AUTOSAR XML (schema 4-0-3)
package /AppBal
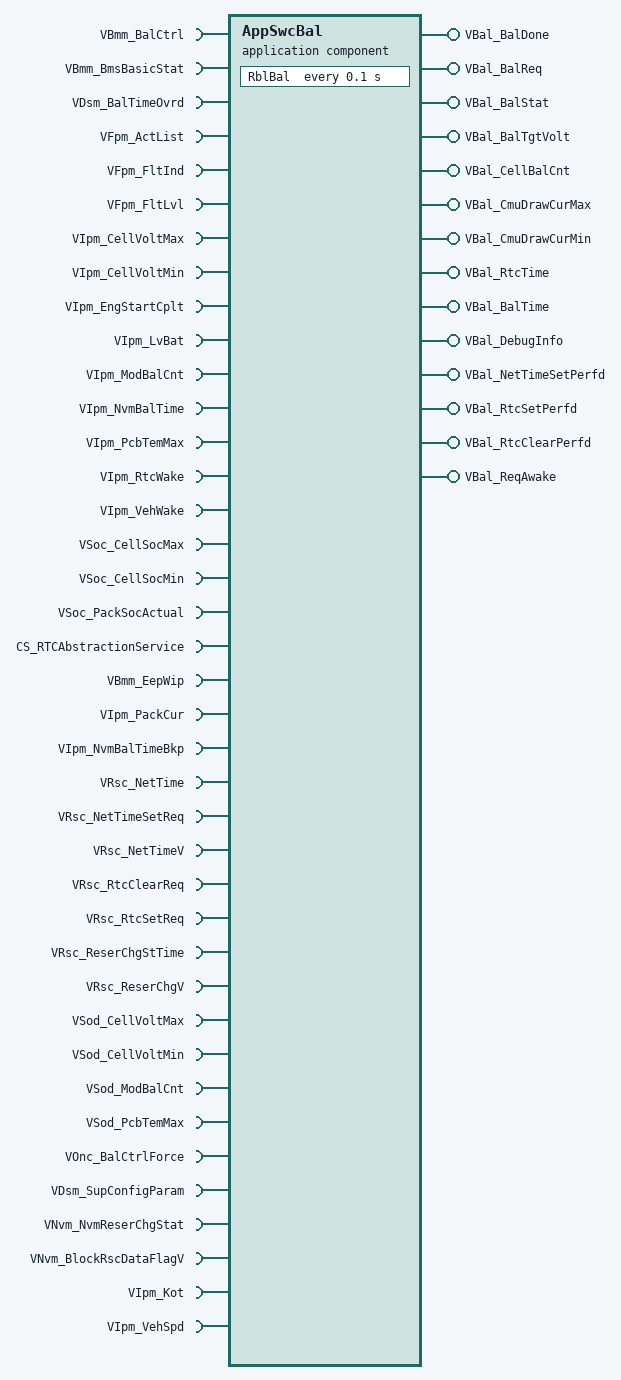
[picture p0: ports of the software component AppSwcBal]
  application sw component type AppSwcBal
    18 x require port:
      VBmm_BalCtrl: nonqueued-receiver-com-spec=Enum, required-interface=VBmm_BalCtrl
      VBmm_BmsBasicStat: nonqueued-receiver-com-spec=Enum, required-interface=VBmm_BmsBasicStat
      VDsm_BalTimeOvrd: nonqueued-receiver-com-spec=Sec, required-interface=VDsm_BalTimeOvrd
      VFpm_ActList: nonqueued-receiver-com-spec=Enum, required-interface=VFpm_ActList
      VFpm_FltInd: nonqueued-receiver-com-spec=Array, required-interface=VFpm_FltInd
      VFpm_FltLvl: nonqueued-receiver-com-spec=Enum, required-interface=VFpm_FltLvl
      VIpm_CellVoltMax: nonqueued-receiver-com-spec=V, required-interface=VIpm_CellVoltMax
      VIpm_CellVoltMin: nonqueued-receiver-com-spec=V, required-interface=VIpm_CellVoltMin
      VIpm_EngStartCplt: nonqueued-receiver-com-spec=Flg, required-interface=VIpm_EngStartCplt
      VIpm_LvBat: nonqueued-receiver-com-spec=V, required-interface=VIpm_LvBat
      VIpm_ModBalCnt: nonqueued-receiver-com-spec=Cnt, required-interface=VIpm_ModBalCnt
      VIpm_NvmBalTime: nonqueued-receiver-com-spec=Sec, required-interface=VIpm_NvmBalTime
      VIpm_PcbTemMax: nonqueued-receiver-com-spec=C, required-interface=VIpm_PcbTemMax
      VIpm_RtcWake: nonqueued-receiver-com-spec=Flg, required-interface=VIpm_RtcWake
      VIpm_VehWake: nonqueued-receiver-com-spec=Flg, required-interface=VIpm_VehWake
      VSoc_CellSocMax: nonqueued-receiver-com-spec=Pct, required-interface=VSoc_CellSocMax
      VSoc_CellSocMin: nonqueued-receiver-com-spec=Pct, required-interface=VSoc_CellSocMin
      VSoc_PackSocActual: nonqueued-receiver-com-spec=Pct, required-interface=VSoc_PackSocActual
    8 x provide port:
      VBal_BalDone: nonqueued-sender-com-spec=Flg, provided-interface=VBal_BalDone
      VBal_BalReq: nonqueued-sender-com-spec=Flg, provided-interface=VBal_BalReq
      VBal_BalStat: nonqueued-sender-com-spec=Enum, provided-interface=VBal_BalStat
      VBal_BalTgtVolt: nonqueued-sender-com-spec{data-element=V, init-value=fields=[5095, 0, 0, 0]}, provided-interface=VBal_BalTgtVolt
      VBal_CellBalCnt: nonqueued-sender-com-spec=Cnt, provided-interface=VBal_CellBalCnt
      VBal_CmuDrawCurMax: nonqueued-sender-com-spec=A, provided-interface=VBal_CmuDrawCurMax
      VBal_CmuDrawCurMin: nonqueued-sender-com-spec=A, provided-interface=VBal_CmuDrawCurMin
      VBal_RtcTime: nonqueued-sender-com-spec=Structure, provided-interface=VBal_RtcTime
    require port CS_RTCAbstractionService: required-interface=CS_RTCAbstractionService
    provide port VBal_BalTime: nonqueued-sender-com-spec=Sec, provided-interface=VBal_BalTime
    require port VBmm_EepWip: nonqueued-receiver-com-spec=Flg, required-interface=VBmm_EepWip
    require port VIpm_PackCur: nonqueued-receiver-com-spec=A, required-interface=VIpm_PackCur
    require port VIpm_NvmBalTimeBkp: nonqueued-receiver-com-spec=Sec, required-interface=VIpm_NvmBalTimeBkp
    provide port VBal_DebugInfo: nonqueued-sender-com-spec=Array, provided-interface=VBal_DebugInfo
    5 x require port:
      VRsc_NetTime: nonqueued-receiver-com-spec=Array, required-interface=VRsc_NetTime
      VRsc_NetTimeSetReq: nonqueued-receiver-com-spec=Flg, required-interface=VRsc_NetTimeSetReq
      VRsc_NetTimeV: nonqueued-receiver-com-spec=Flg, required-interface=VRsc_NetTimeV
      VRsc_RtcClearReq: nonqueued-receiver-com-spec=Flg, required-interface=VRsc_RtcClearReq
      VRsc_RtcSetReq: nonqueued-receiver-com-spec=Flg, required-interface=VRsc_RtcSetReq
    provide port VBal_NetTimeSetPerfd: nonqueued-sender-com-spec=Flg, provided-interface=VBal_NetTimeSetPerfd
    provide port VBal_RtcSetPerfd: nonqueued-sender-com-spec=Flg, provided-interface=VBal_RtcSetPerfd
    provide port VBal_RtcClearPerfd: nonqueued-sender-com-spec=Flg, provided-interface=VBal_RtcClearPerfd
    7 x require port:
      VRsc_ReserChgStTime: nonqueued-receiver-com-spec=Array, required-interface=VRsc_ReserChgStTime
      VRsc_ReserChgV: nonqueued-receiver-com-spec=Flg, required-interface=VRsc_ReserChgV
      VSod_CellVoltMax: nonqueued-receiver-com-spec=V, required-interface=VSod_CellVoltMax
      VSod_CellVoltMin: nonqueued-receiver-com-spec=V, required-interface=VSod_CellVoltMin
      VSod_ModBalCnt: nonqueued-receiver-com-spec=Cnt, required-interface=VSod_ModBalCnt
      VSod_PcbTemMax: nonqueued-receiver-com-spec=C, required-interface=VSod_PcbTemMax
      VOnc_BalCtrlForce: nonqueued-receiver-com-spec=Enum, required-interface=VOnc_BalCtrlForce
    provide port VBal_ReqAwake: nonqueued-sender-com-spec=Flg, provided-interface=VBal_ReqAwake
    5 x require port:
      VDsm_SupConfigParam: nonqueued-receiver-com-spec=Enum, required-interface=VDsm_SupConfigParam
      VNvm_NvmReserChgStat: nonqueued-receiver-com-spec=Enum, required-interface=VNvm_NvmReserChgStat
      VNvm_BlockRscDataFlagV: nonqueued-receiver-com-spec=Flg, required-interface=VNvm_BlockRscDataFlagV
      VIpm_Kot: nonqueued-receiver-com-spec=Sec, required-interface=VIpm_Kot
      VIpm_VehSpd: nonqueued-receiver-com-spec=Kph, required-interface=VIpm_VehSpd
    behavior IbvBal
      timing event TeBal: start-on-event=RblBal, period=0.1
      runnable RblBal: symbol=sym_RblBal
        data-receive-point-by-arguments:
          38 x access:
            ArgRecPoint_VBmm_BalCtrl_Enum: accessed-variable=VBmm_BalCtrl.Enum
            ArgRecPoint_VBmm_BmsBasicStat_Enum: accessed-variable=VBmm_BmsBasicStat.Enum
            ArgRecPoint_VDsm_BalTimeOvrd_Sec: accessed-variable=VDsm_BalTimeOvrd.Sec
            ArgRecPoint_VFpm_ActList_Enum: accessed-variable=VFpm_ActList.Enum
            ArgRecPoint_VFpm_FltInd_Array: accessed-variable=VFpm_FltInd.Array
            ArgRecPoint_VFpm_FltLvl_Enum: accessed-variable=VFpm_FltLvl.Enum
            ArgRecPoint_VSoc_CellSocMax_Pct: accessed-variable=VSoc_CellSocMax.Pct
            ArgRecPoint_VSoc_CellSocMin_Pct: accessed-variable=VSoc_CellSocMin.Pct
            ArgRecPoint_VSoc_PackSocActual_Pct: accessed-variable=VSoc_PackSocActual.Pct
            ArgRecPoint_VIpm_CellVoltMax_V: accessed-variable=VIpm_CellVoltMax.V
            ArgRecPoint_VIpm_CellVoltMin_V: accessed-variable=VIpm_CellVoltMin.V
            ArgRecPoint_VIpm_EngStartCplt_Flg: accessed-variable=VIpm_EngStartCplt.Flg
            ArgRecPoint_VIpm_LvBat_V: accessed-variable=VIpm_LvBat.V
            ArgRecPoint_VIpm_ModBalCnt_Cnt: accessed-variable=VIpm_ModBalCnt.Cnt
            ArgRecPoint_VIpm_NvmBalTime_Sec: accessed-variable=VIpm_NvmBalTime.Sec
            ArgRecPoint_VIpm_PcbTemMax_C: accessed-variable=VIpm_PcbTemMax.C
            ArgRecPoint_VIpm_RtcWake_Flg: accessed-variable=VIpm_RtcWake.Flg
            ArgRecPoint_VIpm_VehWake_Flg: accessed-variable=VIpm_VehWake.Flg
            ArgRecPoint_VBmm_EepWip_Flg: accessed-variable=VBmm_EepWip.Flg
            ArgRecPoint_VIpm_PackCur_A: accessed-variable=VIpm_PackCur.A
            ArgRecPoint_VIpm_NvmBalTimeBkp_Sec: accessed-variable=VIpm_NvmBalTimeBkp.Sec
            ArgRecPoint_VRsc_NetTime_Array: accessed-variable=VRsc_NetTime.Array
            ArgRecPoint_VRsc_NetTimeSetReq_Flg: accessed-variable=VRsc_NetTimeSetReq.Flg
            ArgRecPoint_VRsc_NetTimeV_Flg: accessed-variable=VRsc_NetTimeV.Flg
            ArgRecPoint_VRsc_RtcClearReq_Flg: accessed-variable=VRsc_RtcClearReq.Flg
            ArgRecPoint_VRsc_RtcSetReq_Flg: accessed-variable=VRsc_RtcSetReq.Flg
            ArgRecPoint_VRsc_ReserChgStTime_Array: accessed-variable=VRsc_ReserChgStTime.Array
            ArgRecPoint_VRsc_ReserChgV_Flg: accessed-variable=VRsc_ReserChgV.Flg
            ArgRecPoint_VOnc_BalCtrlForce_Enum: accessed-variable=VOnc_BalCtrlForce.Enum
            ArgRecPoint_VSod_CellVoltMax_V: accessed-variable=VSod_CellVoltMax.V
            ArgRecPoint_VSod_CellVoltMin_V: accessed-variable=VSod_CellVoltMin.V
            ArgRecPoint_VSod_ModBalCnt_Cnt: accessed-variable=VSod_ModBalCnt.Cnt
            ArgRecPoint_VSod_PcbTemMax_C: accessed-variable=VSod_PcbTemMax.C
            ArgRecPoint_VDsm_SupConfigParam_Enum: accessed-variable=VDsm_SupConfigParam.Enum
            ArgRecPoint_VNvm_NvmReserChgStat_Enum: accessed-variable=VNvm_NvmReserChgStat.Enum
            ArgRecPoint_VNvm_BlockRscDataFlagV_Flg: accessed-variable=VNvm_BlockRscDataFlagV.Flg
            ArgRecPoint_VIpm_Kot_Sec: accessed-variable=VIpm_Kot.Sec
            ArgRecPoint_VIpm_VehSpd_Kph: accessed-variable=VIpm_VehSpd.Kph
        data-send-points:
          14 x access:
            SendPoint_VBal_BalDone_Flg: accessed-variable=VBal_BalDone.Flg
            SendPoint_VBal_BalReq_Flg: accessed-variable=VBal_BalReq.Flg
            SendPoint_VBal_BalStat_Enum: accessed-variable=VBal_BalStat.Enum
            SendPoint_VBal_BalTgtVolt_V: accessed-variable=VBal_BalTgtVolt.V
            SendPoint_VBal_CellBalCnt_Cnt: accessed-variable=VBal_CellBalCnt.Cnt
            SendPoint_VBal_CmuDrawCurMax_A: accessed-variable=VBal_CmuDrawCurMax.A
            SendPoint_VBal_CmuDrawCurMin_A: accessed-variable=VBal_CmuDrawCurMin.A
            SendPoint_VBal_RtcTime_C: accessed-variable=VBal_RtcTime.Structure
            SendPoint_VBal_BalTime_Sec: accessed-variable=VBal_BalTime.Sec
            SendPoint_VBal_DebugInfo_Array: accessed-variable=VBal_DebugInfo.Array
            SendPoint_VBal_NetTimeSetPerfd_Flg: accessed-variable=VBal_NetTimeSetPerfd.Flg
            SendPoint_VBal_RtcClearPerfd_Flg: accessed-variable=VBal_RtcClearPerfd.Flg
            SendPoint_VBal_RtcSetPerfd_Flg: accessed-variable=VBal_RtcSetPerfd.Flg
            SendPoint_VBal_ReqAwake_Flg: accessed-variable=VBal_ReqAwake.Flg
        5 x sync call, all with timeout=0.0:
          SynchSrvCallPoint_CS_RTCAbstractionService_SetClock: operation=CS_RTCAbstractionService.SetClock
          SynchSrvCallPoint_CS_RTCAbstractionService_SetAlarm: operation=CS_RTCAbstractionService.SetAlarm
          SynchSrvCallPoint_CS_RTCAbstractionService_GetAlarm: operation=CS_RTCAbstractionService.GetAlarm
          SynchSrvCallPoint_CS_RTCAbstractionService_ClearAlarm: operation=CS_RTCAbstractionService.ClearAlarm
          SynchSrvCallPoint_CS_RTCAbstractionService_GetClock: operation=CS_RTCAbstractionService.GetClock
  swc implementation ImpBal: programming-language=C, sw-version=1.0.0, vendor-id=31, behavior=IbvBal
